# R7FA8D1BH register map
Vendor: Renesas; Series: RA8; File version: 1.2
CPU: CM85 r0p0, little endian, MPU, FPU, VTOR, 4 interrupt priority bits
Registers are 32-bit, read-write, reset 0x0 unless marked. A register's access mark holds for its fields unless they carry their own. Offsets are from the block's base; [hi:lo] are bit positions; {n}, {i} and the like mark numbered series; 'fields as' and 'values as' point back to an identical list.

## DSILINK (part 2 of 4)
Base 0x40346000
Same registers: DSILINK_NS 0x50346000
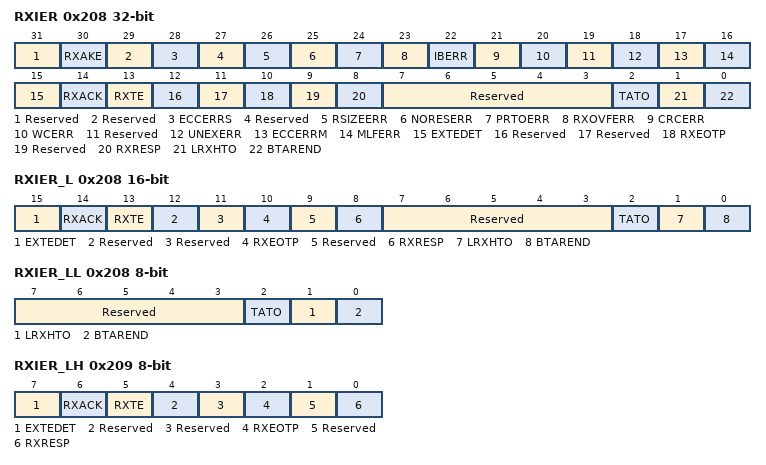
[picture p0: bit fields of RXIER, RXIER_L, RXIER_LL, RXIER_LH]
0x208 RXIER — Receive Interrupt Enable Register
  [31] Reserved — This bit is read as 0. The write value should be 0.
  [30] RXAKE — Acknowledge and Error Report Receive Interrupt Enable
    0=Disable; 1=Enable
  [29] Reserved — This bit is read as 0. The write value should be 0.
  [28] ECCERRS — Single Bit ECC Error Interrupt Enable
    0=Disable; 1=Enable
  [27] Reserved — This bit is read as 0. The write value should be 0.
  [26] RSIZEERR — Return Packet Size Error Interrupt Enable
    0=Disable; 1=Enable
  [25] NORESERR — No Response Error Interrupt Enable
    0=Disable; 1=Enable
  [24] PRTOERR — Peripheral Response Timeout Error Interrupt Enable
    0=Disable; 1=Enable
  [23] RXOVFERR — Receive Buffer Overflow Error Interrupt Enable
    0=Disable; 1=Enable
  [22] IBERR — Internal Bus Error Interrupt Enable
    0=Disable; 1=Enable
  [21] CRCERR — CRC Error Interrupt Enable
    0=Disable; 1=Enable
  [20] WCERR — Word Count Error Interrupt Enable
    0=Disable; 1=Enable
  [19] Reserved — This bit is read as 0. The write value should be 0.
  [18] UNEXERR — Unexpected Packet Error Interrupt Enable
    0=Disable; 1=Enable
  [17] ECCERRM — Multi Bit ECC Error Interrupt Enable
    0=Disable; 1=Enable
  [16] MLFERR — Malform Error Interrupt Enable
    0=Disable; 1=Enable
  [15] EXTEDET — External Tearing Effect Detect Interrupt Enable
    0=Disable; 1=Enable
  [14] RXACK — ACK Trigger Receive Interrupt Enable
    0=Disable; 1=Enable
  [13] RXTE — Tearing Effect Trigger Receive Interrupt Enable
    0=Disable; 1=Enable
  [12] Reserved — This bit is read as 0. The write value should be 0.
  [11] Reserved — This bit is read as 0. The write value should be 0.
  [10] RXEOTP — EoTp Receive Interrupt Enable
    0=Disable; 1=Enable
  [9] Reserved — This bit is read as 0. The write value should be 0.
  [8] RXRESP — Response Packet Receive Interrupt Enable
    0=Disable; 1=Enable
  [7:3] Reserved — These bits are read as 00000. The write value should be 00000.
  [2] TATO — Turnaround Acknowledge Timeout Interrupt Enable
    0=Disable; 1=Enable
  [1] LRXHTO — LP-RX Host Processor Timeout Interrupt Enable
    0=Disable; 1=Enable
  [0] BTAREND — BTA Request End Interrupt Enable
    0=Disable; 1=Enable
0x208 RXIER_L 16-bit (alternate view of RXIER) — Receive Interrupt Enable Register
  [15] EXTEDET — External Tearing Effect Detect Interrupt Enable
    0=Disable; 1=Enable
  [14] RXACK — ACK Trigger Receive Interrupt Enable
    0=Disable; 1=Enable
  [13] RXTE — Tearing Effect Trigger Receive Interrupt Enable
    0=Disable; 1=Enable
  [12] Reserved — This bit is read as 0. The write value should be 0.
  [11] Reserved — This bit is read as 0. The write value should be 0.
  [10] RXEOTP — EoTp Receive Interrupt Enable
    0=Disable; 1=Enable
  [9] Reserved — This bit is read as 0. The write value should be 0.
  [8] RXRESP — Response Packet Receive Interrupt Enable
    0=Disable; 1=Enable
  [7:3] Reserved — These bits are read as 00000. The write value should be 00000.
  [2] TATO — Turnaround Acknowledge Timeout Interrupt Enable
    0=Disable; 1=Enable
  [1] LRXHTO — LP-RX Host Processor Timeout Interrupt Enable
    0=Disable; 1=Enable
  [0] BTAREND — BTA Request End Interrupt Enable
    0=Disable; 1=Enable
0x208 RXIER_LL 8-bit (alternate view of RXIER) — Receive Interrupt Enable Register
  [7:3] Reserved — These bits are read as 00000. The write value should be 00000.
  [2] TATO — Turnaround Acknowledge Timeout Interrupt Enable
    0=Disable; 1=Enable
  [1] LRXHTO — LP-RX Host Processor Timeout Interrupt Enable
    0=Disable; 1=Enable
  [0] BTAREND — BTA Request End Interrupt Enable
    0=Disable; 1=Enable
0x209 RXIER_LH 8-bit (alternate view of RXIER) — Receive Interrupt Enable Register
  [7] EXTEDET — External Tearing Effect Detect Interrupt Enable
    0=Disable; 1=Enable
  [6] RXACK — ACK Trigger Receive Interrupt Enable
    0=Disable; 1=Enable
  [5] RXTE — Tearing Effect Trigger Receive Interrupt Enable
    0=Disable; 1=Enable
  [4] Reserved — This bit is read as 0. The write value should be 0.
  [3] Reserved — This bit is read as 0. The write value should be 0.
  [2] RXEOTP — EoTp Receive Interrupt Enable
    0=Disable; 1=Enable
  [1] Reserved — This bit is read as 0. The write value should be 0.
  [0] RXRESP — Response Packet Receive Interrupt Enable
    0=Disable; 1=Enable
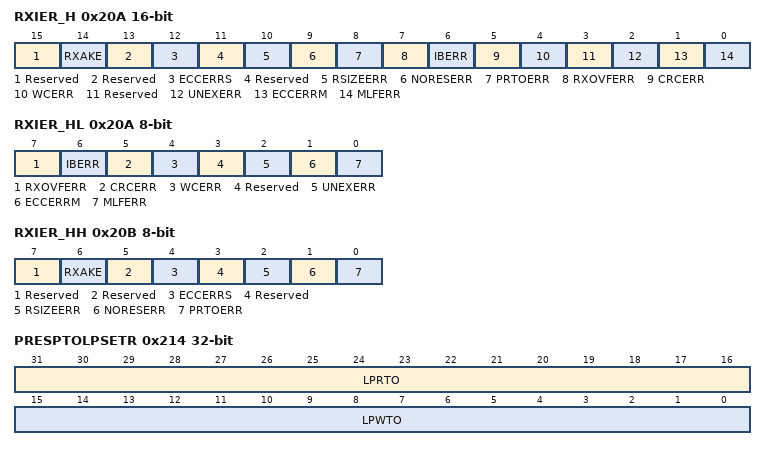
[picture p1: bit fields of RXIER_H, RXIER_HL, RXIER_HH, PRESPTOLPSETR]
0x20A RXIER_H 16-bit (alternate view of RXIER) — Receive Interrupt Enable Register
  [15] Reserved — This bit is read as 0. The write value should be 0.
  [14] RXAKE — Acknowledge and Error Report Receive Interrupt Enable
    0=Disable; 1=Enable
  [13] Reserved — This bit is read as 0. The write value should be 0.
  [12] ECCERRS — Single Bit ECC Error Interrupt Enable
    0=Disable; 1=Enable
  [11] Reserved — This bit is read as 0. The write value should be 0.
  [10] RSIZEERR — Return Packet Size Error Interrupt Enable
    0=Disable; 1=Enable
  [9] NORESERR — No Response Error Interrupt Enable
    0=Disable; 1=Enable
  [8] PRTOERR — Peripheral Response Timeout Error Interrupt Enable
    0=Disable; 1=Enable
  [7] RXOVFERR — Receive Buffer Overflow Error Interrupt Enable
    0=Disable; 1=Enable
  [6] IBERR — Internal Bus Error Interrupt Enable
    0=Disable; 1=Enable
  [5] CRCERR — CRC Error Interrupt Enable
    0=Disable; 1=Enable
  [4] WCERR — Word Count Error Interrupt Enable
    0=Disable; 1=Enable
  [3] Reserved — This bit is read as 0. The write value should be 0.
  [2] UNEXERR — Unexpected Packet Error Interrupt Enable
    0=Disable; 1=Enable
  [1] ECCERRM — Multi Bit ECC Error Interrupt Enable
    0=Disable; 1=Enable
  [0] MLFERR — Malform Error Interrupt Enable
    0=Disable; 1=Enable
0x20A RXIER_HL 8-bit (alternate view of RXIER) — Receive Interrupt Enable Register
  [7] RXOVFERR — Receive Buffer Overflow Error Interrupt Enable
    0=Disable; 1=Enable
  [6] IBERR — Internal Bus Error Interrupt Enable
    0=Disable; 1=Enable
  [5] CRCERR — CRC Error Interrupt Enable
    0=Disable; 1=Enable
  [4] WCERR — Word Count Error Interrupt Enable
    0=Disable; 1=Enable
  [3] Reserved — This bit is read as 0. The write value should be 0.
  [2] UNEXERR — Unexpected Packet Error Interrupt Enable
    0=Disable; 1=Enable
  [1] ECCERRM — Multi Bit ECC Error Interrupt Enable
    0=Disable; 1=Enable
  [0] MLFERR — Malform Error Interrupt Enable
    0=Disable; 1=Enable
0x20B RXIER_HH 8-bit (alternate view of RXIER) — Receive Interrupt Enable Register
  [7] Reserved — This bit is read as 0. The write value should be 0.
  [6] RXAKE — Acknowledge and Error Report Receive Interrupt Enable
    0=Disable; 1=Enable
  [5] Reserved — This bit is read as 0. The write value should be 0.
  [4] ECCERRS — Single Bit ECC Error Interrupt Enable
    0=Disable; 1=Enable
  [3] Reserved — This bit is read as 0. The write value should be 0.
  [2] RSIZEERR — Return Packet Size Error Interrupt Enable
    0=Disable; 1=Enable
  [1] NORESERR — No Response Error Interrupt Enable
    0=Disable; 1=Enable
  [0] PRTOERR — Peripheral Response Timeout Error Interrupt Enable
    0=Disable; 1=Enable
0x210 PRESPTOBTASETR — Peripheral Response Timeout BTA Set Register
  [31:0] PRTBTA — Peripheral Response Timeout Count
0x214 PRESPTOLPSETR — Peripheral Response Timeout LP Set Register
  [31:16] LPRTO — LPDT READ Request Timeout
  [15:0] LPWTO — LPDT WRITE Request Timeout
0x214 PRESPTOLPSETR_L 16-bit (alternate view of PRESPTOLPSETR) — Peripheral Response Timeout LP Set Register
  [15:0] LPWTO — LPDT WRITE Request Timeout
0x216 PRESPTOLPSETR_H 16-bit (alternate view of PRESPTOLPSETR) — Peripheral Response Timeout LP Set Register
  [15:0] LPRTO — LPDT READ Request Timeout
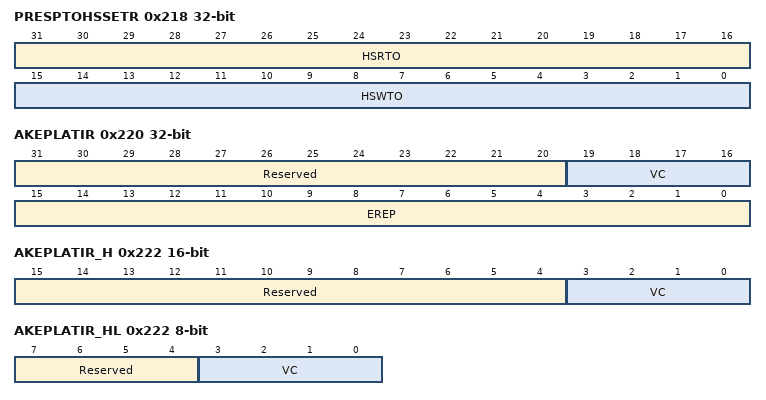
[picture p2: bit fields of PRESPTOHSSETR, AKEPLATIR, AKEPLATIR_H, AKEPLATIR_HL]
0x218 PRESPTOHSSETR — Peripheral Response Timeout HS Set Register
  [31:16] HSRTO — HS READ Request Timeout
  [15:0] HSWTO — HS WRITE Request Timeout
0x218 PRESPTOHSSETR_L 16-bit (alternate view of PRESPTOHSSETR) — Peripheral Response Timeout HS Set Register
  [15:0] HSWTO — HS WRITE Request Timeout
0x21A PRESPTOHSSETR_H 16-bit (alternate view of PRESPTOHSSETR) — Peripheral Response Timeout HS Set Register
  [15:0] HSRTO — HS READ Request Timeout
0x220 AKEPLATIR ro — Acknowledge and Error Report Packet Parameter Latest Info Register
  [31:20] Reserved — These bits are read as 000000000000.
  [19:16] VC — Virtual Channel ID
    0=No Error Report received; 1=From VC-0; 2=From VC-1; 4=From VC-2; 8=From VC-3
  [15:0] EREP — Error Report
0x220 AKEPLATIR_L 16-bit ro (alternate view of AKEPLATIR) — Acknowledge and Error Report Packet Parameter Latest Info Register
  [15:0] EREP — Error Report
0x220 AKEPLATIR_LL 8-bit ro (alternate view of AKEPLATIR) — Acknowledge and Error Report Packet Parameter Latest Info Register
  [7:0] EREP — Error Report
0x221 AKEPLATIR_LH 8-bit ro (alternate view of AKEPLATIR) — Acknowledge and Error Report Packet Parameter Latest Info Register
  [7:0] EREP — Error Report
0x222 AKEPLATIR_H 16-bit ro (alternate view of AKEPLATIR) — Acknowledge and Error Report Packet Parameter Latest Info Register
  [15:4] Reserved — These bits are read as 000000000000.
  [3:0] VC — Virtual Channel ID
    values as AKEPLATIR.VC
0x222 AKEPLATIR_HL 8-bit ro (alternate view of AKEPLATIR) — Acknowledge and Error Report Packet Parameter Latest Info Register
  [7:4] Reserved — These bits are read as 0000.
  [3:0] VC — Virtual Channel ID
    values as AKEPLATIR.VC
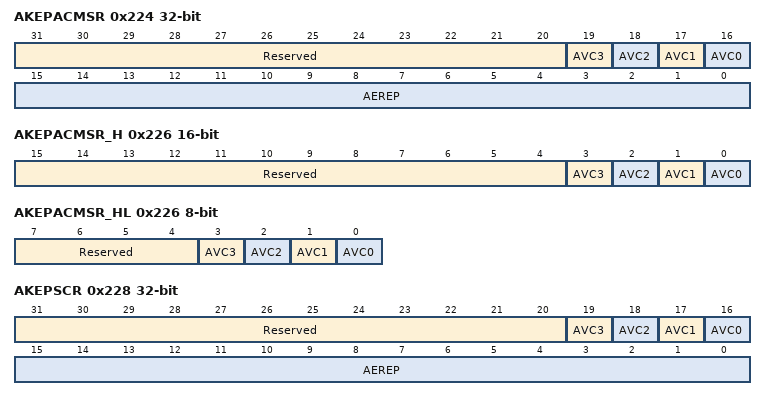
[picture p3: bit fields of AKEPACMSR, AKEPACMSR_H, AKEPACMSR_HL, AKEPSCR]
0x224 AKEPACMSR ro — Acknowledge and Error Report Packet Parameter Accumulate Status Register
  [31:20] Reserved — These bits are read as 000000000000.
  [n+16] AVC{n} (n=0..3) — Virtual Channel-{n} Accumulated Information
    0=No Error Report received from VC-{n}; 1=Received an Acknowledge and Error Report from VC-{n}
  [15:0] AEREP — Accumulated Error Report
0x224 AKEPACMSR_L 16-bit ro (alternate view of AKEPACMSR) — Acknowledge and Error Report Packet Parameter Accumulate Status Register
  [15:0] AEREP — Accumulated Error Report
0x224 AKEPACMSR_LL 8-bit ro (alternate view of AKEPACMSR) — Acknowledge and Error Report Packet Parameter Accumulate Status Register
  [7:0] AEREP — Accumulated Error Report
0x225 AKEPACMSR_LH 8-bit ro (alternate view of AKEPACMSR) — Acknowledge and Error Report Packet Parameter Accumulate Status Register
  [7:0] AEREP — Accumulated Error Report
0x226 AKEPACMSR_H 16-bit ro (alternate view of AKEPACMSR) — Acknowledge and Error Report Packet Parameter Accumulate Status Register
  [15:4] Reserved — These bits are read as 000000000000.
  [n] AVC{n} (n=0..3) — Virtual Channel-{n} Accumulated Information
    values as AKEPACMSR.AVC0
0x226 AKEPACMSR_HL 8-bit ro (alternate view of AKEPACMSR) — Acknowledge and Error Report Packet Parameter Accumulate Status Register
  [7:4] Reserved — These bits are read as 0000.
  [n] AVC{n} (n=0..3) — Virtual Channel-{n} Accumulated Information
    values as AKEPACMSR.AVC0
0x228 AKEPSCR — Acknowledge and Error Report Packet Parameter Status Clear Register
  [31:20] Reserved — These bits are read as 000000000000. The write value should be 000000000000.
  [n+16] AVC{n} write-1-clears read-modifies (n=0..3) — Virtual Channel-{n} Accumulated Information Clear
    0=No operation; 1=Clear the AKEPACMSR.AVC{n} bit
  [15:0] AEREP write-1-clears read-modifies — Accumulated Error Report Clear
    0=No operation; 1=Clear the AKEPACMSR.AEREP[15:0] bits
0x228 AKEPSCR_L 16-bit (alternate view of AKEPSCR) — Acknowledge and Error Report Packet Parameter Status Clear Register
  [15:0] AEREP write-1-clears read-modifies — Accumulated Error Report Clear
    0=No operation
0x228 AKEPSCR_LL 8-bit (alternate view of AKEPSCR) — Acknowledge and Error Report Packet Parameter Status Clear Register
  [7:0] AEREP write-1-clears read-modifies — Accumulated Error Report Clear
    0=No operation; 1=Clear the AKEPACMSR.AEREP[15:0] bits
0x229 AKEPSCR_LH 8-bit (alternate view of AKEPSCR) — Acknowledge and Error Report Packet Parameter Status Clear Register
  fields as AKEPSCR_LL
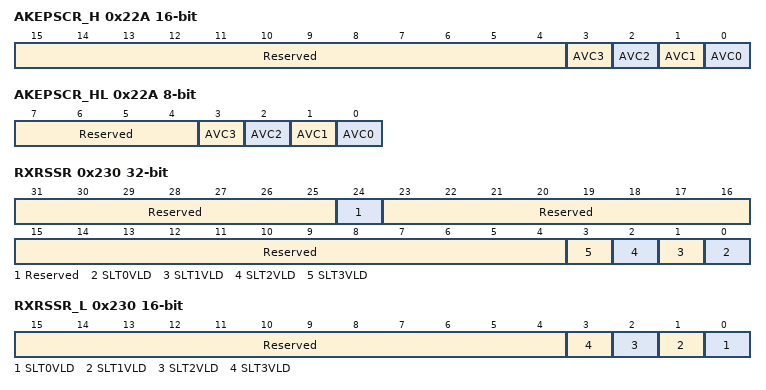
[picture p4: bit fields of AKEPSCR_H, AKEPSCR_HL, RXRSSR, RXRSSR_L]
0x22A AKEPSCR_H 16-bit (alternate view of AKEPSCR) — Acknowledge and Error Report Packet Parameter Status Clear Register
  [15:4] Reserved — These bits are read as 000000000000. The write value should be 000000000000.
  [n] AVC{n} write-1-clears read-modifies (n=0..3) — Virtual Channel-{n} Accumulated Information Clear
    0=No operation; 1=Clear the AKEPACMSR.AVC{n} bit
0x22A AKEPSCR_HL 8-bit (alternate view of AKEPSCR) — Acknowledge and Error Report Packet Parameter Status Clear Register
  [7:4] Reserved — These bits are read as 0000. The write value should be 0000.
  [n] AVC{n} write-1-clears read-modifies (n=0..3) — Virtual Channel-{n} Accumulated Information Clear
    0=No operation; 1=Clear the AKEPACMSR.AVC{n} bit
0x230 RXRSSR ro — Receive Result Saved Status Register
  [31:25] Reserved — These bits are read as 0000000.
  [24] Reserved — This bit is read as 0.
  [23:4] Reserved — These bits are read as 00000000000000000000.
  [n] SLT{n}VLD (n=0..3) — Slot-{n} Valid Flag
    0=None received; 1=Response packet is received and stored in the RXRSS{n}R register
0x230 RXRSSR_L 16-bit ro (alternate view of RXRSSR) — Receive Result Saved Status Register
  [15:4] Reserved — These bits are read as 000000000000.
  [n] SLT{n}VLD (n=0..3) — Slot-{n} Valid Flag
    values as RXRSSR.SLT0VLD
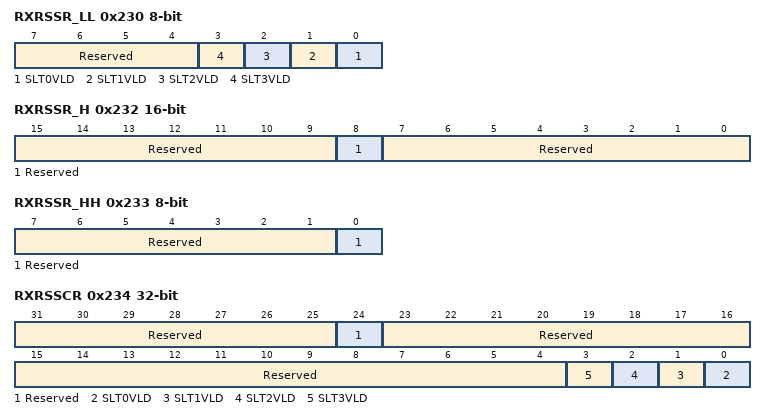
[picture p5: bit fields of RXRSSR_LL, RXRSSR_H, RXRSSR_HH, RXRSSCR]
0x230 RXRSSR_LL 8-bit ro (alternate view of RXRSSR) — Receive Result Saved Status Register
  [7:4] Reserved — These bits are read as 0000.
  [n] SLT{n}VLD (n=0..3) — Slot-{n} Valid Flag
    values as RXRSSR.SLT0VLD
0x232 RXRSSR_H 16-bit ro (alternate view of RXRSSR) — Receive Result Saved Status Register
  [15:9] Reserved — These bits are read as 0000000.
  [8] Reserved — This bit is read as 0.
  [7:0] Reserved — These bits are read as 00000000.
0x233 RXRSSR_HH 8-bit ro (alternate view of RXRSSR) — Receive Result Saved Status Register
  [7:1] Reserved — These bits are read as 0000000.
  [0] Reserved — This bit is read as 0.
0x234 RXRSSCR — Receive Result Saved Status Clear Register
  [31:25] Reserved — These bits are read as 0000000. The write value should be 0000000.
  [24] Reserved — This bit is read as 0. The write value should be 0.
  [23:4] Reserved — These bits are read as 00000000000000000000. The write value should be 00000000000000000000.
  [n] SLT{n}VLD write-1-clears read-modifies (n=0..3) — Slot-{n} Valid Flag Clear
    0=No operation; 1=Clear the RXRSSR.SLT{n}VLD flag
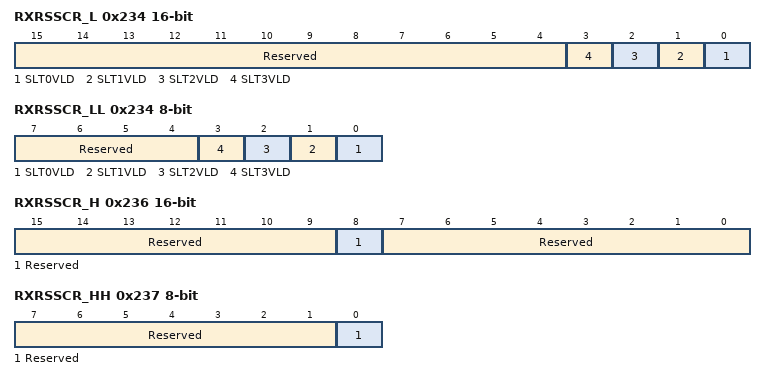
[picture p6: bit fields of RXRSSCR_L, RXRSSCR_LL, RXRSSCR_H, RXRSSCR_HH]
0x234 RXRSSCR_L 16-bit (alternate view of RXRSSCR) — Receive Result Saved Status Clear Register
  [15:4] Reserved — These bits are read as 000000000000. The write value should be 000000000000.
  [n] SLT{n}VLD write-1-clears read-modifies (n=0..3) — Slot-{n} Valid Flag Clear
    0=No operation; 1=Clear the RXRSSR.SLT{n}VLD flag
0x234 RXRSSCR_LL 8-bit ro (alternate view of RXRSSCR) — Receive Result Saved Status Clear Register
  [7:4] Reserved — These bits are read as 0000.
  [n] SLT{n}VLD rw write-1-clears read-modifies (n=0..3) — Slot-{n} Valid Flag Clear
    0=No operation; 1=Clear the RXRSSR.SLT{n}VLD flag
0x236 RXRSSCR_H 16-bit (alternate view of RXRSSCR) — Receive Result Saved Status Clear Register
  [15:9] Reserved — These bits are read as 0000000. The write value should be 0000000.
  [8] Reserved — This bit is read as 0. The write value should be 0.
  [7:0] Reserved — These bits are read as 00000000. The write value should be 00000000.
0x237 RXRSSCR_HH 8-bit (alternate view of RXRSSCR) — Receive Result Saved Status Clear Register
  [7:1] Reserved — These bits are read as 0000000. The write value should be 0000000.
  [0] Reserved — This bit is read as 0. The write value should be 0.
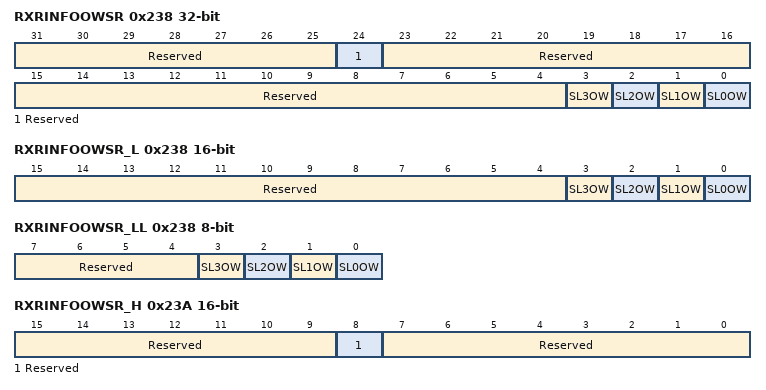
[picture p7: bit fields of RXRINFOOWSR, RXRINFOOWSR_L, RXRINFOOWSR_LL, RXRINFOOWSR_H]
0x238 RXRINFOOWSR ro — Receive Result Info Overwrite Status Register
  [31:25] Reserved — These bits are read as 0000000.
  [24] Reserved — This bit is read as 0.
  [23:4] Reserved — These bits are read as 00000000000000000000.
  [n] SL{n}OW (n=0..3) — Slot-{n} Information Overwrite Flag
    0=No overwritten; 1=Slot-{n} information overwritten
0x238 RXRINFOOWSR_L 16-bit ro (alternate view of RXRINFOOWSR) — Receive Result Info Overwrite Status Register
  [15:4] Reserved — These bits are read as 000000000000.
  [n] SL{n}OW (n=0..3) — Slot-{n} Information Overwrite Flag
    0=No overwritten; 1=Slot-{n} information overwritten
0x238 RXRINFOOWSR_LL 8-bit ro (alternate view of RXRINFOOWSR) — Receive Result Info Overwrite Status Register
  [7:4] Reserved — These bits are read as 0000.
  [n] SL{n}OW (n=0..3) — Slot-{n} Information Overwrite Flag
    0=No overwritten; 1=Slot-{n} information overwritten
0x23A RXRINFOOWSR_H 16-bit ro (alternate view of RXRINFOOWSR) — Receive Result Info Overwrite Status Register
  fields as RXRSSR_H
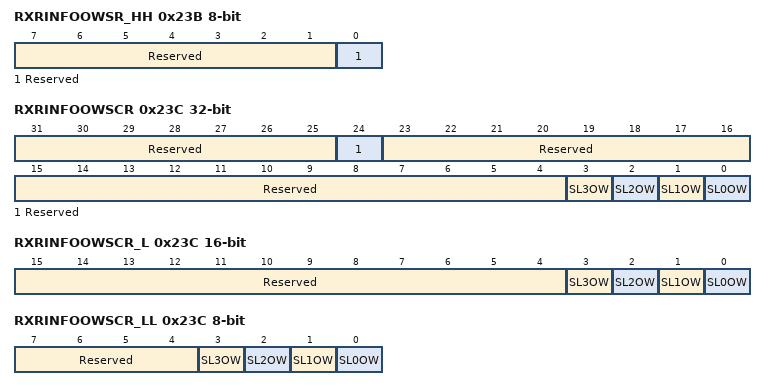
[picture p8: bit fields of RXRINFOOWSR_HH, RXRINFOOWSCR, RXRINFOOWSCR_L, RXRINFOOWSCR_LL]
0x23B RXRINFOOWSR_HH 8-bit ro (alternate view of RXRINFOOWSR) — Receive Result Info Overwrite Status Register
  fields as RXRSSR_HH
0x23C RXRINFOOWSCR — Receive Result Info Overwrite Status Clear Register
  [31:25] Reserved — These bits are read as 0000000. The write value should be 0000000.
  [24] Reserved — This bit is read as 0. The write value should be 0.
  [23:4] Reserved — These bits are read as 00000000000000000000. The write value should be 00000000000000000000.
  [n] SL{n}OW write-1-clears read-modifies (n=0..3) — Slot-{n} Information Overwrite Flag Clear
    0=No operation; 1=Clear the RXRINFOOWSR.SL{n}OW flag
0x23C RXRINFOOWSCR_L 16-bit (alternate view of RXRINFOOWSCR) — Receive Result Info Overwrite Status Clear Register
  [15:4] Reserved — These bits are read as 000000000000. The write value should be 000000000000.
  [n] SL{n}OW write-1-clears read-modifies (n=0..3) — Slot-{n} Information Overwrite Flag Clear
    0=No operation; 1=Clear the RXRINFOOWSR.SL{n}OW flag
0x23C RXRINFOOWSCR_LL 8-bit (alternate view of RXRINFOOWSCR) — Receive Result Info Overwrite Status Clear Register
  [7:4] Reserved — These bits are read as 0000. The write value should be 0000.
  [n] SL{n}OW write-1-clears read-modifies (n=0..3) — Slot-{n} Information Overwrite Flag Clear
    0=No operation; 1=Clear the RXRINFOOWSR.SL{n}OW flag
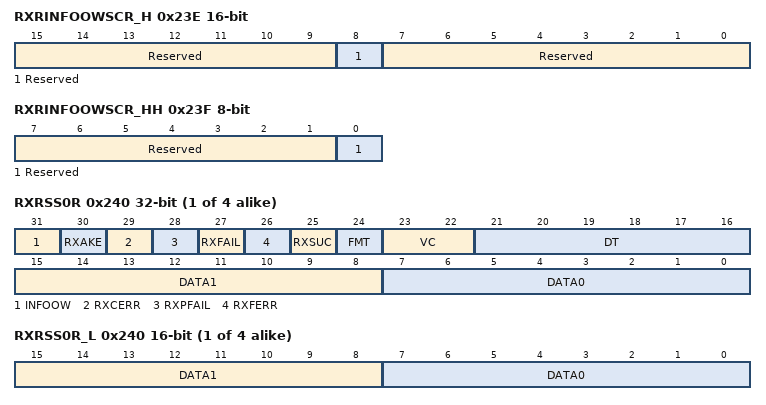
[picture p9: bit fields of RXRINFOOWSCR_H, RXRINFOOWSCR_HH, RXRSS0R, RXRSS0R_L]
0x23E RXRINFOOWSCR_H 16-bit (alternate view of RXRINFOOWSCR) — Receive Result Info Overwrite Status Clear Register
  fields as RXRSSCR_H
0x23F RXRINFOOWSCR_HH 8-bit (alternate view of RXRINFOOWSCR) — Receive Result Info Overwrite Status Clear Register
  fields as RXRSSCR_HH
{0x240+4i} RXRSS{i}R (i=0..3) ro — Receive Result Save Slot-{i} Register
  [31] INFOOW — Information Overwrite
    0=No update; 1=This register information (RXRSSxR[30:0]) was overwritten
  [30] RXAKE — Receive Acknowledge and Error Report Packet
    0=No received; 1=An Acknowledge and Error Report packet received
  [29] RXCERR — Receive Correctable Error
    0=No error; 1=Correctable error detected
  [28] RXPFAIL — Receive Packet Data Fail
    0=No error; 1=Payload data not saved correctly
  [27] RXFAIL — Receive Fail
    0=No error; 1=Expected receive not done
  [26] RXFERR — Fatal Error
    0=No fatal error; 1=Fatal timeout occurred during BTA
  [25] RXSUC — Receive Success
    0=No received; 1=Response packet or ACK trigger received
  [24] FMT — Packet Format
    0=Short packet; 1=Long packet
  [23:22] VC — Virtual Channel
  [21:16] DT — Data Type
  [15:8] DATA1
  [7:0] DATA0
{0x240+4i} RXRSS{i}R_L (i=0..3) 16-bit ro (alternate view of RXRSS{i}R) — Receive Result Save Slot-{i} Register
  [15:8] DATA1, [7:0] DATA0
{0x240+4i} RXRSS{i}R_LL (i=0..3) 8-bit ro (alternate view of RXRSS{i}R) — Receive Result Save Slot-{i} Register
  [7:0] DATA0
{0x241+4i} RXRSS{i}R_LH (i=0..3) 8-bit ro (alternate view of RXRSS{i}R) — Receive Result Save Slot-{i} Register
  [7:0] DATA1
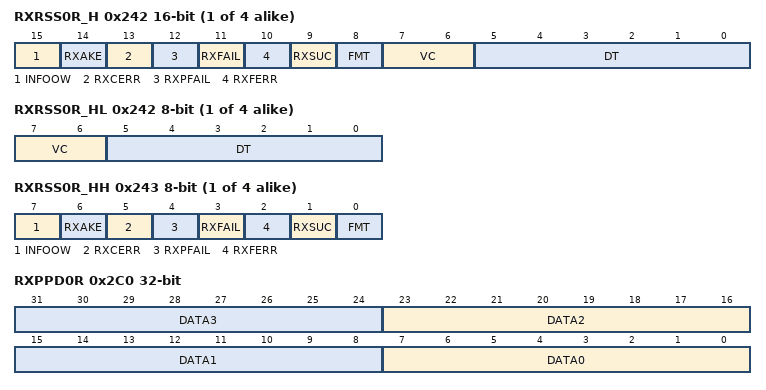
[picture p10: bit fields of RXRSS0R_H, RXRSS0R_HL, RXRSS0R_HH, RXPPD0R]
{0x242+4i} RXRSS{i}R_H (i=0..3) 16-bit ro (alternate view of RXRSS{i}R) — Receive Result Save Slot-{i} Register
  [15] INFOOW — Information Overwrite
    values as RXRSS0R.INFOOW
  [14] RXAKE — Receive Acknowledge and Error Report Packet
    values as RXRSS0R.RXAKE
  [13] RXCERR — Receive Correctable Error
    0=No error; 1=Correctable error detected
  [12] RXPFAIL — Receive Packet Data Fail
    0=No error; 1=Payload data not saved correctly
  [11] RXFAIL — Receive Fail
    0=No error; 1=Expected receive not done
  [10] RXFERR — Fatal Error
    0=No fatal error; 1=Fatal timeout occurred during BTA
  [9] RXSUC — Receive Success
    0=No received; 1=Response packet or ACK trigger received
  [8] FMT — Packet Format
    0=Short packet; 1=Long packet
  [7:6] VC — Virtual Channel
  [5:0] DT — Data Type
{0x242+4i} RXRSS{i}R_HL (i=0..3) 8-bit ro (alternate view of RXRSS{i}R) — Receive Result Save Slot-{i} Register
  [7:6] VC — Virtual Channel
  [5:0] DT — Data Type
{0x243+4i} RXRSS{i}R_HH (i=0..3) 8-bit ro (alternate view of RXRSS{i}R) — Receive Result Save Slot-{i} Register
  [7] INFOOW — Information Overwrite
    values as RXRSS0R.INFOOW
  [6] RXAKE — Receive Acknowledge and Error Report Packet
    values as RXRSS0R.RXAKE
  [5] RXCERR — Receive Correctable Error
    0=No error; 1=Correctable error detected
  [4] RXPFAIL — Receive Packet Data Fail
    0=No error; 1=Payload data not saved correctly
  [3] RXFAIL — Receive Fail
    0=No error; 1=Expected receive not done
  [2] RXFERR — Fatal Error
    0=No fatal error; 1=Fatal timeout occurred during BTA
  [1] RXSUC — Receive Success
    0=No received; 1=Response packet or ACK trigger received
  [0] FMT — Packet Format
    0=Short packet; 1=Long packet
0x2C0 RXPPD0R ro — Receive Packet Payload Data 0 Register
  [8n+7:8n] DATA{n} (n=0..3) — Payload Data {n}
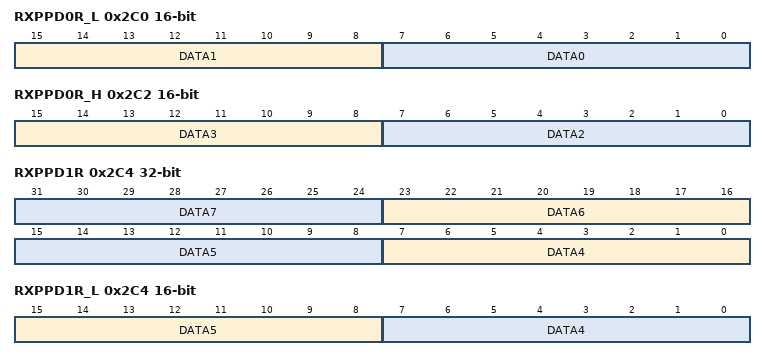
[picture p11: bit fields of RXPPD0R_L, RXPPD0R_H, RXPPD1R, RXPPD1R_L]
0x2C0 RXPPD0R_L 16-bit ro (alternate view of RXPPD0R) — Receive Packet Payload Data 0 Register
  [15:8] DATA1 — Payload Data 1
  [7:0] DATA0 — Payload Data 0
0x2C0 RXPPD0R_LL 8-bit ro (alternate view of RXPPD0R) — Receive Packet Payload Data 0 Register
  [7:0] DATA0 — Payload Data 0
0x2C1 RXPPD0R_LH 8-bit ro (alternate view of RXPPD0R) — Receive Packet Payload Data 0 Register
  [7:0] DATA1 — Payload Data 1
0x2C2 RXPPD0R_H 16-bit ro (alternate view of RXPPD0R) — Receive Packet Payload Data 0 Register
  [15:8] DATA3 — Payload Data 3
  [7:0] DATA2 — Payload Data 2
0x2C2 RXPPD0R_HL 8-bit ro (alternate view of RXPPD0R) — Receive Packet Payload Data 0 Register
  [7:0] DATA2 — Payload Data 2
0x2C3 RXPPD0R_HH 8-bit ro (alternate view of RXPPD0R) — Receive Packet Payload Data 0 Register
  [7:0] DATA3 — Payload Data 3
0x2C4 RXPPD1R ro — Receive Packet Payload Data 1 Register
  [8n-25:8n-32] DATA{n} (n=4..7) — Payload Data {n-4}
0x2C4 RXPPD1R_L 16-bit ro (alternate view of RXPPD1R) — Receive Packet Payload Data 1 Register
  [15:8] DATA5 — Payload Data 1
  [7:0] DATA4 — Payload Data 0
0x2C4 RXPPD1R_LL 8-bit ro (alternate view of RXPPD1R) — Receive Packet Payload Data 1 Register
  [7:0] DATA4 — Payload Data 0
0x2C5 RXPPD1R_LH 8-bit ro (alternate view of RXPPD1R) — Receive Packet Payload Data 1 Register
  [7:0] DATA5 — Payload Data 1
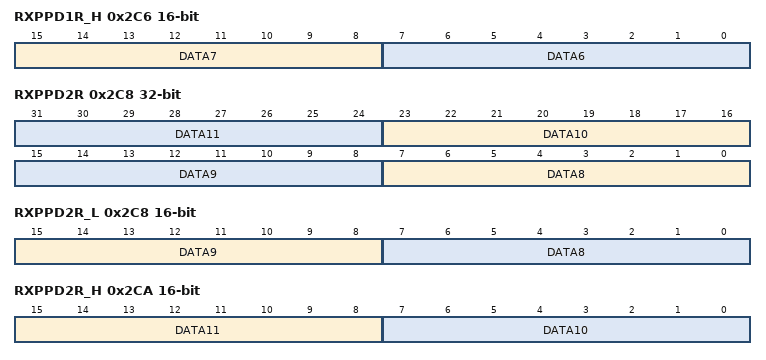
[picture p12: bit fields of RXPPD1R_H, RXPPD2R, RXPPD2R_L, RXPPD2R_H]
0x2C6 RXPPD1R_H 16-bit ro (alternate view of RXPPD1R) — Receive Packet Payload Data 1 Register
  [15:8] DATA7 — Payload Data 3
  [7:0] DATA6 — Payload Data 2
0x2C6 RXPPD1R_HL 8-bit ro (alternate view of RXPPD1R) — Receive Packet Payload Data 1 Register
  [7:0] DATA6 — Payload Data 2
0x2C7 RXPPD1R_HH 8-bit ro (alternate view of RXPPD1R) — Receive Packet Payload Data 1 Register
  [7:0] DATA7 — Payload Data 3
0x2C8 RXPPD2R ro — Receive Packet Payload Data 2 Register
  [8n-57:8n-64] DATA{n} (n=8..11) — Payload Data {n}
0x2C8 RXPPD2R_L 16-bit ro (alternate view of RXPPD2R) — Receive Packet Payload Data 2 Register
  [15:8] DATA9 — Payload Data 9
  [7:0] DATA8 — Payload Data 8
0x2C8 RXPPD2R_LL 8-bit ro (alternate view of RXPPD2R) — Receive Packet Payload Data 2 Register
  [7:0] DATA8 — Payload Data 8
0x2C9 RXPPD2R_LH 8-bit ro (alternate view of RXPPD2R) — Receive Packet Payload Data 2 Register
  [7:0] DATA9 — Payload Data 9
0x2CA RXPPD2R_H 16-bit ro (alternate view of RXPPD2R) — Receive Packet Payload Data 2 Register
  [15:8] DATA11 — Payload Data 11
  [7:0] DATA10 — Payload Data 10
0x2CA RXPPD2R_HL 8-bit ro (alternate view of RXPPD2R) — Receive Packet Payload Data 2 Register
  [7:0] DATA10 — Payload Data 10
0x2CB RXPPD2R_HH 8-bit ro (alternate view of RXPPD2R) — Receive Packet Payload Data 2 Register
  [7:0] DATA11 — Payload Data 11
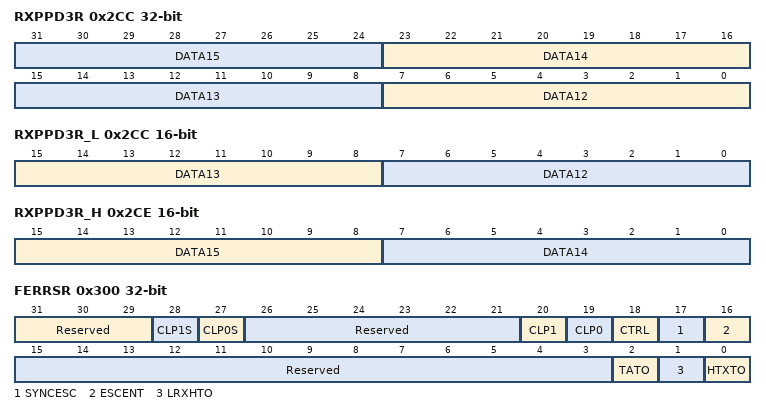
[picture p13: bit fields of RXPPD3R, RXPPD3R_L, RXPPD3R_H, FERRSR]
0x2CC RXPPD3R ro — Receive Packet Payload Data 3 Register
  [8n-89:8n-96] DATA{n} (n=12..15) — Payload Data {n}
0x2CC RXPPD3R_L 16-bit ro (alternate view of RXPPD3R) — Receive Packet Payload Data 3 Register
  [15:8] DATA13 — Payload Data 13
  [7:0] DATA12 — Payload Data 12
0x2CC RXPPD3R_LL 8-bit ro (alternate view of RXPPD3R) — Receive Packet Payload Data 3 Register
  [7:0] DATA12 — Payload Data 12
0x2CD RXPPD3R_LH 8-bit ro (alternate view of RXPPD3R) — Receive Packet Payload Data 3 Register
  [7:0] DATA13 — Payload Data 13
0x2CE RXPPD3R_H 16-bit ro (alternate view of RXPPD3R) — Receive Packet Payload Data 3 Register
  [15:8] DATA15 — Payload Data 15
  [7:0] DATA14 — Payload Data 14
0x2CE RXPPD3R_HL 8-bit ro (alternate view of RXPPD3R) — Receive Packet Payload Data 3 Register
  [7:0] DATA14 — Payload Data 14
0x2CF RXPPD3R_HH 8-bit ro (alternate view of RXPPD3R) — Receive Packet Payload Data 3 Register
  [7:0] DATA15 — Payload Data 15
0x2E0 HSTXTOSETR — HS TX Timeout Set Register
  [31:0] HTXTO — HS TX Timeout Count
0x2E4 LRXHTOSETR — LRX-H Timeout Set Register
  [31:0] LRXHTO — LP-RX Host Processor Timeout
0x2E8 TATOSETR — TA Timeout Set Register
  [31:0] TATO — Turnaround Acknowledge Timeout
0x300 FERRSR ro — Fatal Error Status Register
  [31:29] Reserved — These bits are read as 000.
  [28] CLP1S — LP1 Contention Error Status
    0=Normal state; 1=LP1 Contention Error (ErrContentionLP1) state
  [27] CLP0S — LP0 Contention Error Status
    0=Normal state; 1=LP0 Contention Error (ErrContentionLP0) state
  [26:21] Reserved — These bits are read as 000000.
  [20] CLP1 — LP1 Contention Error Interrupt Flag
    0=No error detected; 1=LP1 Contention Error (ErrContentionLP1) detected
  [19] CLP0 — LP0 Contention Error Interrupt Flag
    0=No error detected; 1=LP0 Contention Error (ErrContentionLP0) detected
  [18] CTRL — Control Error Interrupt Flag
    0=No error detected; 1=Control Error (ErrControl) detected
  [17] SYNCESC — LPDT Sync Error Interrupt Flag
    0=No error detected; 1=LPDT Synchronization Error (ErrSyncEsc) detected
  [16] ESCENT — Escape mode Entry Error Interrupt Flag
    0=No error detected; 1=Escape mode Entry Error (ErrEsc) detected
  [15:3] Reserved — These bits are read as 0000000000000.
  [2] TATO — Turnaround Acknowledge Timeout Interrupt Flag
    0=No detected; 1=Turnaround Acknowledge Timeout (TA_TO) detected
  [1] LRXHTO — LP-RX Host Processor Timeout Interrupt Flag
    0=No detected; 1=LP-RX Host Processor Timeout (LRX-H_TO) detected
  [0] HTXTO — HS TX Timeout Interrupt Flag
    0=No detected; 1=HS TX Timeout (HTX_TO) detected
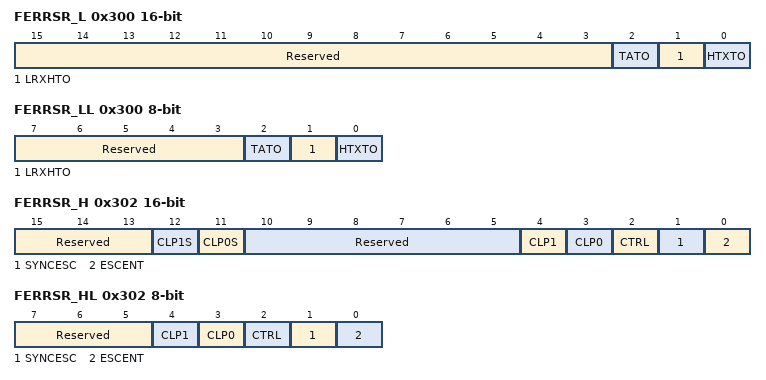
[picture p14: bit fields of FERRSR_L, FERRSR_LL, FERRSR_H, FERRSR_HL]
0x300 FERRSR_L 16-bit ro (alternate view of FERRSR) — Fatal Error Status Register
  [15:3] Reserved — These bits are read as 0000000000000.
  [2] TATO — Turnaround Acknowledge Timeout Interrupt Flag
    values as FERRSR.TATO
  [1] LRXHTO — LP-RX Host Processor Timeout Interrupt Flag
    values as FERRSR.LRXHTO
  [0] HTXTO — HS TX Timeout Interrupt Flag
    0=No detected; 1=HS TX Timeout (HTX_TO) detected
0x300 FERRSR_LL 8-bit ro (alternate view of FERRSR) — Fatal Error Status Register
  [7:3] Reserved — These bits are read as 00000.
  [2] TATO — Turnaround Acknowledge Timeout Interrupt Flag
    values as FERRSR.TATO
  [1] LRXHTO — LP-RX Host Processor Timeout Interrupt Flag
    values as FERRSR.LRXHTO
  [0] HTXTO — HS TX Timeout Interrupt Flag
    0=No detected; 1=HS TX Timeout (HTX_TO) detected
0x302 FERRSR_H 16-bit ro (alternate view of FERRSR) — Fatal Error Status Register
  [15:13] Reserved — These bits are read as 000.
  [12] CLP1S — LP1 Contention Error Status
    values as FERRSR.CLP1S
  [11] CLP0S — LP0 Contention Error Status
    values as FERRSR.CLP0S
  [10:5] Reserved — These bits are read as 000000.
  [4] CLP1 — LP1 Contention Error Interrupt Flag
    values as FERRSR.CLP1
  [3] CLP0 — LP0 Contention Error Interrupt Flag
    values as FERRSR.CLP0
  [2] CTRL — Control Error Interrupt Flag
    0=No error detected; 1=Control Error (ErrControl) detected
  [1] SYNCESC — LPDT Sync Error Interrupt Flag
    values as FERRSR.SYNCESC
  [0] ESCENT — Escape mode Entry Error Interrupt Flag
    values as FERRSR.ESCENT
0x302 FERRSR_HL 8-bit ro (alternate view of FERRSR) — Fatal Error Status Register
  [7:5] Reserved — These bits are read as 000.
  [4] CLP1 — LP1 Contention Error Interrupt Flag
    values as FERRSR.CLP1
  [3] CLP0 — LP0 Contention Error Interrupt Flag
    values as FERRSR.CLP0
  [2] CTRL — Control Error Interrupt Flag
    0=No error detected; 1=Control Error (ErrControl) detected
  [1] SYNCESC — LPDT Sync Error Interrupt Flag
    values as FERRSR.SYNCESC
  [0] ESCENT — Escape mode Entry Error Interrupt Flag
    values as FERRSR.ESCENT
0x303 FERRSR_HH 8-bit ro (alternate view of FERRSR) — Fatal Error Status Register
  [7:5] Reserved — These bits are read as 000.
  [4] CLP1S — LP1 Contention Error Status
    values as FERRSR.CLP1S
  [3] CLP0S — LP0 Contention Error Status
    values as FERRSR.CLP0S
  [2:0] Reserved — These bits are read as 000.
0x304 FERRSCR — Fatal Error Status Clear Register
  [31:21] Reserved — These bits are read as 00000000000. The write value should be 00000000000.
  [20] CLP1 write-1-clears read-modifies — LP1 Contention Error Interrupt Flag Clear
    0=No operation; 1=Clear the FERRSR.CLP1 flag
  [19] CLP0 write-1-clears read-modifies — LP0 Contention Error Interrupt Flag Clear
    0=No operation; 1=Clear the FERRSR.CLP0 flag
  [18] CTRL write-1-clears read-modifies — Control Error Interrupt Flag Clear
    0=No operation; 1=Clear the FERRSR.CTRL flag
  [17] SYNCESC write-1-clears read-modifies — LPDT Sync Error Interrupt Flag Clear
    0=No operation; 1=Clear the FERRSR.SYNCESC flag
  [16] ESCENT write-1-clears read-modifies — Escape mode Entry Error Interrupt Flag Clear
    0=No operation; 1=Clear the FERRSR.ESCENT flag
  [15:3] Reserved — These bits are read as 0000000000000. The write value should be 0000000000000.
  [2] TATO write-1-clears read-modifies — Turnaround Acknowledge Timeout Interrupt Flag Clear
    0=No operation; 1=Clear the FERRSR.TATO flag
  [1] LRXHTO write-1-clears read-modifies — LP-RX Host Processor Timeout Interrupt Flag Clear
    0=No operation; 1=Clear the FERRSR.LRXHTO flag
  [0] HTXTO write-1-clears read-modifies — HS TX Timeout Interrupt Flag Clear
    0=No operation; 1=Clear the FERRSR.HTXTO flag
0x304 FERRSCR_L 16-bit (alternate view of FERRSCR) — Fatal Error Status Clear Register
  [15:3] Reserved — These bits are read as 0000000000000. The write value should be 0000000000000.
  [2] TATO write-1-clears read-modifies — Turnaround Acknowledge Timeout Interrupt Flag Clear
    0=No operation; 1=Clear the FERRSR.TATO flag
  [1] LRXHTO write-1-clears read-modifies — LP-RX Host Processor Timeout Interrupt Flag Clear
    0=No operation; 1=Clear the FERRSR.LRXHTO flag
  [0] HTXTO write-1-clears read-modifies — HS TX Timeout Interrupt Flag Clear
    0=No operation; 1=Clear the FERRSR.HTXTO flag
0x304 FERRSCR_LL 8-bit (alternate view of FERRSCR) — Fatal Error Status Clear Register
  [7:3] Reserved — These bits are read as 00000. The write value should be 00000.
  [2] TATO write-1-clears read-modifies — Turnaround Acknowledge Timeout Interrupt Flag Clear
    0=No operation; 1=Clear the FERRSR.TATO flag
  [1] LRXHTO write-1-clears read-modifies — LP-RX Host Processor Timeout Interrupt Flag Clear
    0=No operation; 1=Clear the FERRSR.LRXHTO flag
  [0] HTXTO write-1-clears read-modifies — HS TX Timeout Interrupt Flag Clear
    0=No operation; 1=Clear the FERRSR.HTXTO flag
0x306 FERRSCR_H 16-bit (alternate view of FERRSCR) — Fatal Error Status Clear Register
  [15:5] Reserved — These bits are read as 00000000000. The write value should be 00000000000.
  [4] CLP1 write-1-clears read-modifies — LP1 Contention Error Interrupt Flag Clear
    0=No operation; 1=Clear the FERRSR.CLP1 flag
  [3] CLP0 write-1-clears read-modifies — LP0 Contention Error Interrupt Flag Clear
    0=No operation; 1=Clear the FERRSR.CLP0 flag
  [2] CTRL write-1-clears read-modifies — Control Error Interrupt Flag Clear
    0=No operation; 1=Clear the FERRSR.CTRL flag
  [1] SYNCESC write-1-clears read-modifies — LPDT Sync Error Interrupt Flag Clear
    0=No operation; 1=Clear the FERRSR.SYNCESC flag
  [0] ESCENT write-1-clears read-modifies — Escape mode Entry Error Interrupt Flag Clear
    0=No operation; 1=Clear the FERRSR.ESCENT flag
0x306 FERRSCR_HL 8-bit (alternate view of FERRSCR) — Fatal Error Status Clear Register
  [7:5] Reserved — These bits are read as 000. The write value should be 000.
  [4] CLP1 write-1-clears read-modifies — LP1 Contention Error Interrupt Flag Clear
    0=No operation; 1=Clear the FERRSR.CLP1 flag
  [3] CLP0 write-1-clears read-modifies — LP0 Contention Error Interrupt Flag Clear
    0=No operation; 1=Clear the FERRSR.CLP0 flag
  [2] CTRL write-1-clears read-modifies — Control Error Interrupt Flag Clear
    0=No operation; 1=Clear the FERRSR.CTRL flag
  [1] SYNCESC write-1-clears read-modifies — LPDT Sync Error Interrupt Flag Clear
    0=No operation; 1=Clear the FERRSR.SYNCESC flag
  [0] ESCENT write-1-clears read-modifies — Escape mode Entry Error Interrupt Flag Clear
    0=No operation; 1=Clear the FERRSR.ESCENT flag
0x308 FERRIER — Fatal Error Interrupt Enable Register
  [31:21] Reserved — These bits are read as 00000000000. The write value should be 00000000000.
  [20] CLP1 — LP1 Contention Error Interrupt Enable
    0=Disable; 1=Enable
  [19] CLP0 — LP0 Contention Error Interrupt Enable
    0=Disable; 1=Enable
  [18] CTRL — Control Error Interrupt Enable
    0=Disable; 1=Enable
  [17] SYNCESC — LPDT Sync Error Interrupt Enable
    0=Disable; 1=Enable
  [16] ESCENT — Escape mode Entry Error Interrupt Enable
    0=Disable; 1=Enable
  [15:3] Reserved — These bits are read as 0000000000000. The write value should be 0000000000000.
  [2] TATO — Turnaround Acknowledge Timeout Interrupt Enable
    0=Disable; 1=Enable
  [1] LRXHTO — LP-RX Host Processor Timeout Interrupt Enable
    0=Disable; 1=Enable
  [0] HTXTO — HS TX Timeout Interrupt Enable
    0=Disable; 1=Enable
0x308 FERRIER_L 16-bit (alternate view of FERRIER) — Fatal Error Interrupt Enable Register
  [15:3] Reserved — These bits are read as 0000000000000. The write value should be 0000000000000.
  [2] TATO — Turnaround Acknowledge Timeout Interrupt Enable
    0=Disable; 1=Enable
  [1] LRXHTO — LP-RX Host Processor Timeout Interrupt Enable
    0=Disable; 1=Enable
  [0] HTXTO — HS TX Timeout Interrupt Enable
    0=Disable; 1=Enable
0x308 FERRIER_LL 8-bit (alternate view of FERRIER) — Fatal Error Interrupt Enable Register
  [7:3] Reserved — These bits are read as 00000. The write value should be 00000.
  [2] TATO — Turnaround Acknowledge Timeout Interrupt Enable
    0=Disable; 1=Enable
  [1] LRXHTO — LP-RX Host Processor Timeout Interrupt Enable
    0=Disable; 1=Enable
  [0] HTXTO — HS TX Timeout Interrupt Enable
    0=Disable; 1=Enable
0x30A FERRIER_H 16-bit (alternate view of FERRIER) — Fatal Error Interrupt Enable Register
  [15:5] Reserved — These bits are read as 00000000000. The write value should be 00000000000.
  [4] CLP1 — LP1 Contention Error Interrupt Enable
    0=Disable; 1=Enable
  [3] CLP0 — LP0 Contention Error Interrupt Enable
    0=Disable; 1=Enable
  [2] CTRL — Control Error Interrupt Enable
    0=Disable; 1=Enable
  [1] SYNCESC — LPDT Sync Error Interrupt Enable
    0=Disable; 1=Enable
  [0] ESCENT — Escape mode Entry Error Interrupt Enable
    0=Disable; 1=Enable
0x30A FERRIER_HL 8-bit (alternate view of FERRIER) — Fatal Error Interrupt Enable Register
  [7:5] Reserved — These bits are read as 000. The write value should be 000.
  [4] CLP1 — LP1 Contention Error Interrupt Enable
    0=Disable; 1=Enable
  [3] CLP0 — LP0 Contention Error Interrupt Enable
    0=Disable; 1=Enable
  [2] CTRL — Control Error Interrupt Enable
    0=Disable; 1=Enable
  [1] SYNCESC — LPDT Sync Error Interrupt Enable
    0=Disable; 1=Enable
  [0] ESCENT — Escape mode Entry Error Interrupt Enable
    0=Disable; 1=Enable
0x314 CLSTPTSETR — Clock Lane Stop Time Set Register
  [31:24] CLKKPT — Clock Keep Time
  [23:16] CLKBFHT — Clock Beforehand Time
  [15:12] Reserved — These bits are read as 0000. The write value should be 0000.
  [11:2] CLKSTPT — Clock Stop Time
  [1:0] Reserved — These bits are read as 00. The write value should be 00.
0x314 CLSTPTSETR_L 16-bit (alternate view of CLSTPTSETR) — Clock Lane Stop Time Set Register
  [15:12] Reserved — These bits are read as 0000. The write value should be 0000.
  [11:2] CLKSTPT — Clock Stop Time
  [1:0] Reserved — These bits are read as 00. The write value should be 00.
0x314 CLSTPTSETR_LL 8-bit (alternate view of CLSTPTSETR) — Clock Lane Stop Time Set Register
  [7:2] CLKSTPT — Clock Stop Time
  [1:0] Reserved — These bits are read as 00. The write value should be 00.
0x315 CLSTPTSETR_LH 8-bit (alternate view of CLSTPTSETR) — Clock Lane Stop Time Set Register
  [7:4] Reserved — These bits are read as 0000. The write value should be 0000.
  [3:0] CLKSTPT — Clock Stop Time
0x316 CLSTPTSETR_H 16-bit (alternate view of CLSTPTSETR) — Clock Lane Stop Time Set Register
  [15:8] CLKKPT — Clock Keep Time
  [7:0] CLKBFHT — Clock Beforehand Time
0x316 CLSTPTSETR_HL 8-bit (alternate view of CLSTPTSETR) — Clock Lane Stop Time Set Register
  [7:0] CLKBFHT — Clock Beforehand Time
0x317 CLSTPTSETR_HH 8-bit (alternate view of CLSTPTSETR) — Clock Lane Stop Time Set Register
  [7:0] CLKKPT — Clock Keep Time
